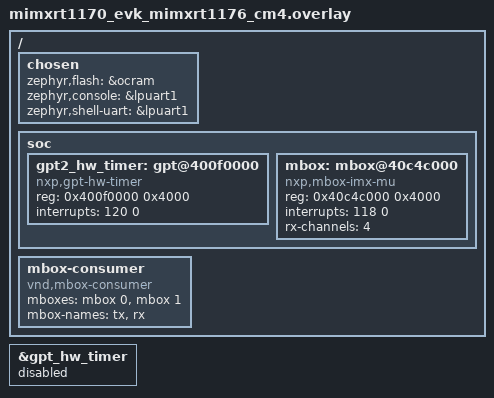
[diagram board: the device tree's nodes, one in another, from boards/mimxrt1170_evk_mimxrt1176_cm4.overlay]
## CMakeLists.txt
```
#
# Copyright 2023-2026 NXP
#
# SPDX-License-Identifier: BSD-3-Clause
#

cmake_minimum_required(VERSION 3.20.0)

find_package(Zephyr REQUIRED HINTS $ENV{ZEPHYR_BASE})

if(("${BOARD}" STREQUAL "mimxrt1170_evkb") OR
  ("${BOARD}" STREQUAL "mimxrt1170_evk") OR
  ("${BOARD}" STREQUAL "mimxrt685_evk") OR
  ("${BOARD}" STREQUAL "mimxrt700_evk") OR
  ("${BOARD}" STREQUAL "mimxrt1160_evk"))
  message(STATUS "${BOARD} compile as remote in this sample")
else()
  message(FATAL_ERROR "${BOARD} is not supported for this sample")
endif()

project(remote)

message(STATUS "${BOARD} compiles as remote in this sample")

target_include_directories(app PRIVATE ${CMAKE_CURRENT_SOURCE_DIR}/..)

enable_language(C CXX)

target_include_directories(app PRIVATE
    ${PROJECT_SOURCE_DIR}/..
    ${PROJECT_SOURCE_DIR}/src
    ${PROJECT_SOURCE_DIR}/src/service
)

target_sources(app PRIVATE
    # Main files
    ${PROJECT_SOURCE_DIR}/src/main.cpp
    ${PROJECT_SOURCE_DIR}/src/erpc_error_handler.cpp

    # Generated shim code
    ${PROJECT_SOURCE_DIR}/src/service/c_erpc_matrix_multiply_server.cpp
    ${PROJECT_SOURCE_DIR}/src/service/erpc_matrix_multiply_server.cpp
    ${PROJECT_SOURCE_DIR}/src/service/erpc_matrix_multiply_interface.cpp
)

# Same for erpc library and erpc_config.h
target_include_directories(erpc PRIVATE ${CMAKE_CURRENT_SOURCE_DIR}/..)

if (CONFIG_BOARD_MIMXRT685_EVK OR CONFIG_BOARD_MIMXRT700_EVK)
    include("${ZEPHYR_BASE}/samples/boards/nxp/adsp/rtxxx/common/remote-dsp-imgs.cmake")
endif()
```

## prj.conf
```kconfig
# C++ Language Support
CONFIG_CPP=y
CONFIG_STD_CPP20=y
CONFIG_NEWLIB_LIBC=y
CONFIG_GLIBCXX_LIBCPP=y

# Compiler
CONFIG_MAIN_STACK_SIZE=4096
CONFIG_HEAP_MEM_POOL_SIZE=8192
CONFIG_NO_OPTIMIZATIONS=y

# eRPC
CONFIG_ERPC=y
CONFIG_ERPC_TRANSPORT_MBOX=y

# MBOX
CONFIG_MBOX=y

CONFIG_STDOUT_CONSOLE=n
```

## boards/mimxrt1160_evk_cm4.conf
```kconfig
CONFIG_MBOX_NXP_IMX_MU=y
CONFIG_BUILD_OUTPUT_INFO_HEADER=y
CONFIG_BUILD_OUTPUT_HEX=y
CONFIG_SECOND_CORE_MCUX=y
```

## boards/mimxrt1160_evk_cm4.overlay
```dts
/*
 * Copyright 2023 NXP
 *
 * SPDX-License-Identifier: Apache-2.0
 */

/ {
	chosen {
		zephyr,flash = &ocram;
		zephyr,console = &lpuart1;
		zephyr,shell-uart = &lpuart1;

		/* Delete ipc chosen property where old IPM mailbox driver bellow is
		 * configured.
		 */
		/delete-property/ zephyr,ipc;
	};

	soc {
		/delete-node/ gpt@400f0000;

		/* Replace GPT2 with another GPT kernel timer */
		gpt2_hw_timer:gpt@400f0000 {
			compatible = "nxp,gpt-hw-timer";
			reg = <0x400f0000 0x4000>;
			interrupts = <120 0>;
			status = "okay";
		};

		/* Delete IPM Driver node nxp,imx-mu */
		/delete-node/ mailbox@40c4c000;

		/* Attach MBOX driver to MU Unit */
		mbox:mbox@40c4c000 {
			compatible = "nxp,mbox-imx-mu";
			reg = <0x40c4c000 0x4000>;
			interrupts = <118 0>;
			rx-channels = <4>;
			#mbox-cells = <1>;
			status = "okay";
		};
	};
};

/* Disable primary GPT timer */
&gpt_hw_timer {
	status = "disabled";
};
```

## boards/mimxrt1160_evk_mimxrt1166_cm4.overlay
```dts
/*
 * Copyright 2023-2024 NXP
 *
 * SPDX-License-Identifier: BSD-3-Clause
 */

/ {
	chosen {
		zephyr,flash = &ocram;
		zephyr,console = &lpuart1;
		zephyr,shell-uart = &lpuart1;

		/* Delete ipc chosen property where old IPM mailbox driver bellow is
		 * configured.
		 */
		/delete-property/ zephyr,ipc;
	};

	soc {
		/delete-node/ gpt@400f0000;

		/* Replace GPT2 with another GPT kernel timer */
		gpt2_hw_timer:gpt@400f0000 {
			compatible = "nxp,gpt-hw-timer";
			reg = <0x400f0000 0x4000>;
			interrupts = <120 0>;
			status = "okay";
		};

		/* Delete IPM Driver node nxp,imx-mu */
		/delete-node/ mailbox@40c4c000;

		/* Attach MBOX driver to MU Unit */
		mbox:mbox@40c4c000 {
			compatible = "nxp,mbox-imx-mu";
			reg = <0x40c4c000 0x4000>;
			interrupts = <118 0>;
			rx-channels = <4>;
			#mbox-cells = <1>;
			status = "okay";
		};
	};
};

/* Disable primary GPT timer */
&gpt_hw_timer {
	status = "disabled";
};
```

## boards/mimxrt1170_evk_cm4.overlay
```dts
/*
 * Copyright 2023-2024 NXP
 *
 * SPDX-License-Identifier: BSD-3-Clause
 */

/ {
	chosen {
		zephyr,flash = &ocram;
		zephyr,console = &lpuart1;
		zephyr,shell-uart = &lpuart1;

		/* Delete ipc chosen property where old IPM mailbox driver bellow is
		 * configured.
		 */
		/delete-property/ zephyr,ipc;
	};

	soc {
		/delete-node/ gpt@400f0000;

		/* Replace GPT2 with another GPT kernel timer */
		gpt2_hw_timer:gpt@400f0000 {
			compatible = "nxp,gpt-hw-timer";
			reg = <0x400f0000 0x4000>;
			interrupts = <120 0>;
			status = "okay";
		};

		/* Delete IPM Driver node nxp,imx-mu */
		/delete-node/ mailbox@40c4c000;

		/* Attach MBOX driver to MU Unit */
		mbox:mbox@40c4c000 {
			compatible = "nxp,mbox-imx-mu";
			reg = <0x40c4c000 0x4000>;
			interrupts = <118 0>;
			rx-channels = <4>;
			#mbox-cells = <1>;
			status = "okay";
		};
	};
};

/* Disable primary GPT timer */
&gpt_hw_timer {
	status = "disabled";
};
```

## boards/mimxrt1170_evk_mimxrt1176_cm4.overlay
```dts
/*
 * Copyright 2023-2024 NXP
 *
 * SPDX-License-Identifier: BSD-3-Clause
 */

/ {
	chosen {
		zephyr,flash = &ocram;
		zephyr,console = &lpuart1;
		zephyr,shell-uart = &lpuart1;

		/* Delete ipc chosen property where old IPM mailbox driver bellow is
		 * configured.
		 */
		/delete-property/ zephyr,ipc;
	};

	soc {
		/delete-node/ gpt@400f0000;

		/* Replace GPT2 with another GPT kernel timer */
		gpt2_hw_timer:gpt@400f0000 {
			compatible = "nxp,gpt-hw-timer";
			reg = <0x400f0000 0x4000>;
			interrupts = <120 0>;
			status = "okay";
		};

		/* Delete IPM Driver node nxp,imx-mu */
		/delete-node/ mailbox@40c4c000;

		/* Attach MBOX driver to MU Unit */
		mbox:mbox@40c4c000 {
			compatible = "nxp,mbox-imx-mu";
			reg = <0x40c4c000 0x4000>;
			interrupts = <118 0>;
			rx-channels = <4>;
			#mbox-cells = <1>;
			status = "okay";
		};
	};

	mbox-consumer {
		compatible = "vnd,mbox-consumer";
		mboxes = <&mbox 0>, <&mbox 1>;
		mbox-names = "tx", "rx";
	};
};

/* Disable primary GPT timer */
&gpt_hw_timer {
	status = "disabled";
};
```

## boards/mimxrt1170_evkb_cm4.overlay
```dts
/*
 * Copyright 2023-2024 NXP
 *
 * SPDX-License-Identifier: BSD-3-Clause
 */

/ {
	chosen {
		zephyr,flash = &ocram;
		zephyr,console = &lpuart1;
		zephyr,shell-uart = &lpuart1;

		/* Delete ipc chosen property where old IPM mailbox driver bellow is
		 * configured.
		 */
		/delete-property/ zephyr,ipc;
	};

	soc {
		/delete-node/ gpt@400f0000;

		/* Replace GPT2 with another GPT kernel timer */
		gpt2_hw_timer:gpt@400f0000 {
			compatible = "nxp,gpt-hw-timer";
			reg = <0x400f0000 0x4000>;
			interrupts = <120 0>;
			status = "okay";
		};

		/* Delete IPM Driver node nxp,imx-mu */
		/delete-node/ mailbox@40c4c000;

		/* Attach MBOX driver to MU Unit */
		mbox:mbox@40c4c000 {
			compatible = "nxp,mbox-imx-mu";
			reg = <0x40c4c000 0x4000>;
			interrupts = <118 0>;
			rx-channels = <4>;
			#mbox-cells = <1>;
			status = "okay";
		};
	};

};

/* Disable primary GPT timer */
&gpt_hw_timer {
	status = "disabled";
};
```

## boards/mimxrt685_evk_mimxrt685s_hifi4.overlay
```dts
/*
 * Copyright 2026 NXP
 *
 * SPDX-License-Identifier: Apache-2.0
 */

#include <zephyr/dt-bindings/ipc_service/static_vrings.h>
#include <zephyr/dt-bindings/memory-attr/memory-attr-arm.h>

/ {
	mbox-consumer {
		compatible = "vnd,mbox-consumer";
		mboxes = <&mbox 0>, <&mbox 1>;
		mbox-names = "tx", "rx";
	};
};
```

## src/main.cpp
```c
/*
 * Copyright 2023-2026 NXP
 *
 * SPDX-License-Identifier: BSD-3-Clause
 */

#include <zephyr/kernel.h>
#include <zephyr/drivers/mbox.h>

#include "erpc_server_setup.h"
#include "erpc_mbox_zephyr_transport.hpp"
#include "erpc_error_handler.h"

#include "erpc_matrix_multiply_common.h"
#include "c_erpc_matrix_multiply_server.h"

/*******************************************************************************
 * Definitions
 ******************************************************************************/
#define TX_ID (0)
#define RX_ID (1)

/*******************************************************************************
 * Prototypes
 ******************************************************************************/

/*******************************************************************************
 * Code
 ******************************************************************************/

/*!
 * @brief erpcMatrixMultiply function implementation.
 *
 * This is the implementation of the erpcMatrixMultiply function called by the primary core.
 *
 * @param matrix1 First matrix
 * @param matrix2 Second matrix
 * @param result_matrix Result matrix
 */
void erpcMatrixMultiply(Matrix matrix1, Matrix matrix2, Matrix result_matrix)
{
    int32_t i, j, k;

    /* Clear the result matrix */
    for (i = 0; i < matrix_size; ++i)
    {
        for (j = 0; j < matrix_size; ++j)
        {
            result_matrix[i][j] = 0;
        }
    }

    /* Multiply two matrices */
    for (i = 0; i < matrix_size; ++i)
    {
        for (j = 0; j < matrix_size; ++j)
        {
            for (k = 0; k < matrix_size; ++k)
            {
                result_matrix[i][j] += matrix1[i][k] * matrix2[k][j];
            }
        }
    }
}

/*!
 * @brief Main function
 */
int main(void)
{
    const struct mbox_dt_spec rx_channel = MBOX_DT_SPEC_GET(DT_PATH(mbox_consumer), rx);
    const struct mbox_dt_spec tx_channel = MBOX_DT_SPEC_GET(DT_PATH(mbox_consumer), tx);
    const struct device *dev;

    erpc_transport_t transport;
    erpc_server_t server;

    dev = DEVICE_DT_GET(DT_NODELABEL(mbox));
    printk("REMOTE: MTU %d\n", mbox_mtu_get(dev));

    transport = erpc_transport_zephyr_mbox_init((void *)dev, (void *)&tx_channel, (void *)&rx_channel);

    /* MessageBufferFactory initialization */
    erpc_mbf_t message_buffer_factory;
    message_buffer_factory = erpc_mbf_dynamic_init();

    /* eRPC server side initialization */
    server = erpc_server_init(transport, message_buffer_factory);

    /* adding the service to the server */
    erpc_service_t service = create_MatrixMultiplyService_service();
    erpc_add_service_to_server(server, service);

    for (;;)
    {
        /* process message */
        erpc_status_t status = erpc_server_poll(server);

        /* handle error status */
        if (status != (erpc_status_t)kErpcStatus_Success)
        {
            /* print error description */
            erpc_error_handler(status, 0);

            /* removing the service from the server */
            erpc_remove_service_from_server(server, service);
            destroy_MatrixMultiplyService_service(service);

            /* stop erpc server */
            erpc_server_stop(server);

            /* print error description */
            erpc_server_deinit(server);

            /* exit program loop */
            break;
        }

        /* do other tasks */
        int32_t i;
        for (i = 0; i < 10000; i++)
        {
        }
    }
    for (;;)
    {
    }
}
```
